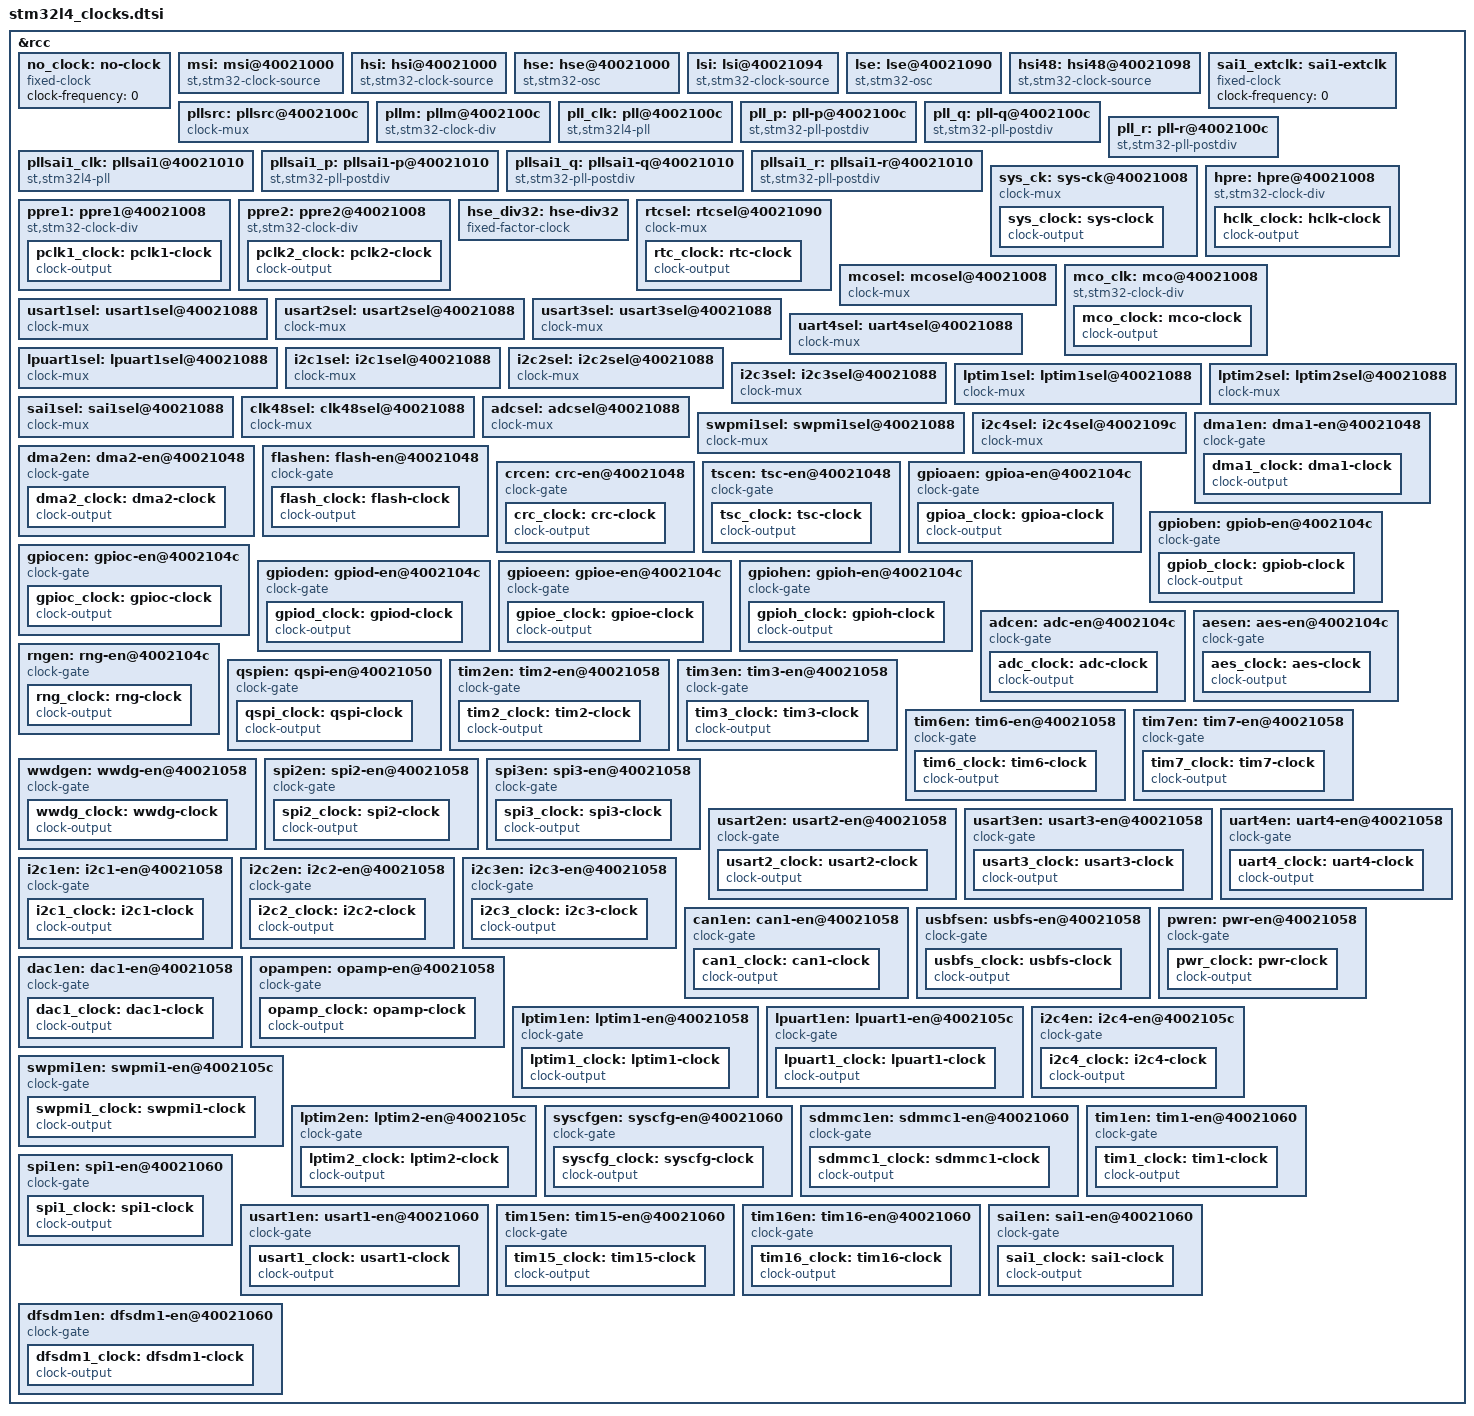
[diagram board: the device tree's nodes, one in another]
/*
 * Copyright (c) 2026 Analog Devices Inc.
 *
 * SPDX-License-Identifier: Apache-2.0
 */

/*
 * Clock tree for the STMicroelectronics STM32L4x (RM0394).
 *
 * Modeled on the STM32H7 clock devicetree: every configurable element of
 * the RCC is described as a node, and the 'reg' property of each node points
 * at the register (RCC base 0x4002_1000) used to configure it. Where a node
 * produces an observable output that a consumer can use, a "clock-output"
 * child node is added.
 *
 * Per-peripheral clock enables (e.g. USART2EN) are modeled as "clock-gate"
 * children of their kernel clock mux, each with its own "clock-output" child.
 *
 * RCC register offsets used below (relative to 0x40021000):
 *   RCC_CR          0x00    RCC_ICSCR       0x04    RCC_CFGR        0x08
 *   RCC_PLLCFGR     0x0C    RCC_PLLSAI1CFGR 0x10
 *   RCC_AHB1ENR     0x48    RCC_AHB2ENR     0x4C    RCC_AHB3ENR     0x50
 *   RCC_APB1ENR1    0x58    RCC_APB1ENR2    0x5C    RCC_APB2ENR     0x60
 *   RCC_CCIPR       0x88    RCC_BDCR        0x90    RCC_CSR         0x94
 *   RCC_CRRCR       0x98    RCC_CCIPR2      0x9C
 */

&rcc {
	#address-cells = <1>;
	#size-cells = <1>;

	/* ----------------------------------------------------------------- */
	/* Root clock sources (oscillators)                                  */
	/* ----------------------------------------------------------------- */

	no_clock: no-clock {
		compatible = "fixed-clock";
		#clock-cells = <0>;
		clock-frequency = <0>;
	};

	msi: msi@40021000 {
		/*
		 * Multi-Speed Internal RC oscillator (100 kHz - 48 MHz).
		 * Default after reset: 4 MHz (MSIRANGE = 6).
		 */
		compatible = "st,stm32-clock-source";
		#clock-cells = <1>;
		/* RCC_CR[MSION] */
		reg = <0x40021000 0x1>;
		offset = <0x0>;
		ready-offset = <0x1>;
		frequency = <4000000>;
	};

	hsi: hsi@40021000 {
		/* 16 MHz high-speed internal RC oscillator */
		compatible = "st,stm32-clock-source";
		#clock-cells = <1>;
		/* RCC_CR[HSION] */
		reg = <0x40021000 0x1>;
		offset = <0x8>;
		ready-offset = <0xa>;
		frequency = <16000000>;
	};

	hse: hse@40021000 {
		/* External high-speed oscillator (crystal or bypass, 4-48 MHz) */
		compatible = "st,stm32-osc";
		#clock-cells = <2>;
		/* RCC_CR[HSEON] */
		reg = <0x40021000 0x1>;
		offset = <0x10>;
		ready-offset = <0x11>;
		bypass-offset = <0x12>;
		frequency = <8000000>;
		#address-cells = <1>;
		#size-cells = <1>;
	};

	lsi: lsi@40021094 {
		/* ~32 kHz low-speed internal RC oscillator */
		compatible = "st,stm32-clock-source";
		#clock-cells = <1>;
		/* RCC_CSR[LSION] */
		reg = <0x40021094 0x1>;
		offset = <0x0>;
		ready-offset = <0x1>;
		frequency = <32000>;
	};

	lse: lse@40021090 {
		/* 32.768 kHz external low-speed oscillator (backup domain) */
		compatible = "st,stm32-osc";
		#clock-cells = <2>;
		/* RCC_BDCR[LSEON] */
		reg = <0x40021090 0x1>;
		offset = <0x0>;
		ready-offset = <0x1>;
		bypass-offset = <0x2>;
		frequency = <32768>;
	};

	hsi48: hsi48@40021098 {
		/* 48 MHz internal RC oscillator (USB/CRS) */
		compatible = "st,stm32-clock-source";
		#clock-cells = <1>;
		/* RCC_CRRCR[HSI48ON] */
		reg = <0x40021098 0x1>;
		offset = <0x0>;
		ready-offset = <0x1>;
		frequency = <48000000>;
	};

	sai1_extclk: sai1-extclk {
		compatible = "fixed-clock";
		#clock-cells = <0>;
		clock-frequency = <0>;
	};

	/* ----------------------------------------------------------------- */
	/* PLL reference clock source mux and input divider                  */
	/* ----------------------------------------------------------------- */

	/*
	 * RCC_PLLCFGR[PLLSRC] - common source for PLL and PLLSAI1.
	 * 00 = None, 01 = MSI, 10 = HSI16, 11 = HSE
	 */
	pllsrc: pllsrc@4002100c {
		compatible = "clock-mux";
		#clock-cells = <1>;
		reg = <0x4002100c 0x2>;
		offset = <0x0>;
		input-sources = <&no_clock &msi &hsi &hse>;
		#address-cells = <1>;
		#size-cells = <1>;
	};

	/*
	 * RCC_PLLCFGR[PLLM] - shared input divider for all PLLs.
	 * Bits [6:4], 3 bits, div 1..8 (field value + 1).
	 */
	pllm: pllm@4002100c {
		compatible = "st,stm32-clock-div";
		#clock-cells = <1>;
		reg = <0x4002100c 0x1>;
		offset = <0x4>;
		width = <0x3>;
		div-type = "linear-aon";
		input = <&pllsrc>;
	};

	/* ----------------------------------------------------------------- */
	/* Main PLL - VCO and P/Q/R post-dividers                           */
	/* ----------------------------------------------------------------- */

	/*
	 * Main PLL VCO.
	 * RCC_PLLCFGR[PLLN] (bits [14:8]): VCO multiplier (8..86).
	 * f(VCO) = f(PLL input) / PLLM * PLLN
	 * RCC_CR[PLLON] bit 24, PLLRDY bit 25.
	 *
	 * This needs a dedicated STM32L4 PLL driver (compatible "st,stm32l4-pll").
	 */
	pll_clk: pll@4002100c {
		compatible = "st,stm32l4-pll";
		reg = <0x4002100c 0x4>, <0x40021000 0x4>;
		#clock-cells = <2>;
		/* RCC_CR[PLLON] */
		enable-bit = <0x18>;
		input = <&pllm>;
		#address-cells = <1>;
		#size-cells = <1>;
	};

	pll_p: pll-p@4002100c {
		/*
		 * RCC_PLLCFGR[PLLP] bit 17: 0=/7, 1=/17
		 * (or PLLPDIV[4:0] bits [31:27] override when nonzero: /2../31)
		 * RCC_PLLCFGR[PLLPEN] bit 16.
		 */
		compatible = "st,stm32-pll-postdiv";
		div-type = "l4p";
		#clock-cells = <1>;
		enable-offset = <0x10>;
		reg = <0x4002100c 0x4>, <0x4002100c 0x4>;
		offset = <0x1b>;
		width = <0x5>;
		input = <&pll_clk>;
	};

	pll_q: pll-q@4002100c {
		/*
		 * RCC_PLLCFGR[PLLQ] bits [22:21]: 00=2, 01=4, 10=6, 11=8
		 * RCC_PLLCFGR[PLLQEN] bit 20.
		 */
		compatible = "st,stm32-pll-postdiv";
		div-type = "l4";
		#clock-cells = <1>;
		enable-offset = <0x14>;
		reg = <0x4002100c 0x4>, <0x4002100c 0x4>;
		offset = <0x15>;
		width = <0x2>;
		input = <&pll_clk>;
	};

	pll_r: pll-r@4002100c {
		/*
		 * RCC_PLLCFGR[PLLR] bits [26:25]: 00=2, 01=4, 10=6, 11=8
		 * RCC_PLLCFGR[PLLREN] bit 24.
		 */
		compatible = "st,stm32-pll-postdiv";
		div-type = "l4";
		#clock-cells = <1>;
		enable-offset = <0x18>;
		reg = <0x4002100c 0x4>, <0x4002100c 0x4>;
		offset = <0x19>;
		width = <0x2>;
		input = <&pll_clk>;
	};

	/* ----------------------------------------------------------------- */
	/* PLLSAI1 - VCO and P/Q/R post-dividers                            */
	/* ----------------------------------------------------------------- */

	/*
	 * PLLSAI1 VCO.
	 * RCC_PLLSAI1CFGR[PLLSAI1N] (bits [14:8]): VCO multiplier (8..86).
	 * Shares PLLSRC and PLLM with main PLL.
	 * RCC_CR[PLLSAI1ON] bit 26, PLLSAI1RDY bit 27.
	 */
	pllsai1_clk: pllsai1@40021010 {
		compatible = "st,stm32l4-pll";
		reg = <0x40021010 0x4>, <0x40021000 0x4>;
		#clock-cells = <2>;
		/* RCC_CR[PLLSAI1ON] */
		enable-bit = <0x1a>;
		input = <&pllm>;
		#address-cells = <1>;
		#size-cells = <1>;
	};

	pllsai1_p: pllsai1-p@40021010 {
		/*
		 * RCC_PLLSAI1CFGR[PLLSAI1P] bit 17: 0=/7, 1=/17
		 * (or PLLSAI1PDIV[4:0] bits [31:27] override when nonzero)
		 * RCC_PLLSAI1CFGR[PLLSAI1PEN] bit 16.
		 */
		compatible = "st,stm32-pll-postdiv";
		div-type = "l4p";
		#clock-cells = <1>;
		enable-offset = <0x10>;
		reg = <0x40021010 0x4>, <0x40021010 0x4>;
		offset = <0x1b>;
		width = <0x5>;
		input = <&pllsai1_clk>;
	};

	pllsai1_q: pllsai1-q@40021010 {
		/*
		 * RCC_PLLSAI1CFGR[PLLSAI1Q] bits [22:21]: 00=2, 01=4, 10=6, 11=8
		 * RCC_PLLSAI1CFGR[PLLSAI1QEN] bit 20.
		 */
		compatible = "st,stm32-pll-postdiv";
		div-type = "l4";
		#clock-cells = <1>;
		enable-offset = <0x14>;
		reg = <0x40021010 0x4>, <0x40021010 0x4>;
		offset = <0x15>;
		width = <0x2>;
		input = <&pllsai1_clk>;
	};

	pllsai1_r: pllsai1-r@40021010 {
		/*
		 * RCC_PLLSAI1CFGR[PLLSAI1R] bits [26:25]: 00=2, 01=4, 10=6, 11=8
		 * RCC_PLLSAI1CFGR[PLLSAI1REN] bit 24.
		 */
		compatible = "st,stm32-pll-postdiv";
		div-type = "l4";
		#clock-cells = <1>;
		enable-offset = <0x18>;
		reg = <0x40021010 0x4>, <0x40021010 0x4>;
		offset = <0x19>;
		width = <0x2>;
		input = <&pllsai1_clk>;
	};

	/* ----------------------------------------------------------------- */
	/* System clock (SYSCLK) and bus clock generation                    */
	/* ----------------------------------------------------------------- */

	sys_ck: sys-ck@40021008 {
		/*
		 * RCC_CFGR[SW] bits [1:0] - system clock source mux.
		 * 00 = MSI, 01 = HSI16, 10 = HSE, 11 = PLL_R
		 */
		compatible = "clock-mux";
		#clock-cells = <1>;
		reg = <0x40021008 0x2>;
		offset = <0x0>;
		input-sources = <&msi &hsi &hse &pll_r>;

		sys_clock: sys-clock {
			compatible = "clock-output";
			#clock-cells = <0>;
		};
	};

	hpre: hpre@40021008 {
		/*
		 * RCC_CFGR[HPRE] bits [7:4] - AHB prescaler.
		 * 0xxx=/1, 1000=/2, 1001=/4, ..., 1111=/512
		 */
		compatible = "st,stm32-clock-div";
		#clock-cells = <1>;
		reg = <0x40021008 0x1>;
		offset = <0x4>;
		width = <0x4>;
		div-type = "pow2";
		input = <&sys_ck>;

		hclk_clock: hclk-clock {
			compatible = "clock-output";
			#clock-cells = <0>;
		};
	};

	ppre1: ppre1@40021008 {
		/*
		 * RCC_CFGR[PPRE1] bits [10:8] - APB1 prescaler.
		 * 0xx=HCLK/1, 100=/2, 101=/4, 110=/8, 111=/16
		 */
		compatible = "st,stm32-clock-div";
		#clock-cells = <1>;
		reg = <0x40021008 0x1>;
		offset = <0x8>;
		width = <0x3>;
		div-type = "pow2";
		input = <&hpre>;

		pclk1_clock: pclk1-clock {
			compatible = "clock-output";
			#clock-cells = <0>;
		};
	};

	ppre2: ppre2@40021008 {
		/*
		 * RCC_CFGR[PPRE2] bits [13:11] - APB2 prescaler.
		 * 0xx=HCLK/1, 100=/2, 101=/4, 110=/8, 111=/16
		 */
		compatible = "st,stm32-clock-div";
		#clock-cells = <1>;
		reg = <0x40021008 0x2>;
		offset = <0xb>;
		width = <0x3>;
		div-type = "pow2";
		input = <&hpre>;

		pclk2_clock: pclk2-clock {
			compatible = "clock-output";
			#clock-cells = <0>;
		};
	};

	/* ----------------------------------------------------------------- */
	/* RTC clock - RCC_BDCR[RTCSEL]                                      */
	/* ----------------------------------------------------------------- */

	hse_div32: hse-div32 {
		compatible = "fixed-factor-clock";
		#clock-cells = <0>;
		clock-div = <32>;
		clock-mult = <1>;
		clocks = <&hse 0 0>;
	};

	rtcsel: rtcsel@40021090 {
		/*
		 * RCC_BDCR[RTCSEL] bits [9:8] - RTC clock source mux.
		 * 00 = None, 01 = LSE, 10 = LSI, 11 = HSE/32
		 */
		compatible = "clock-mux";
		#clock-cells = <1>;
		reg = <0x40021090 0x2>;
		offset = <0x8>;
		input-sources = <&no_clock &lse &lsi &hse_div32>;

		rtc_clock: rtc-clock {
			compatible = "clock-output";
			#clock-cells = <0>;
		};
	};

	/* ----------------------------------------------------------------- */
	/* Micro-controller clock output (MCO) - RCC_CFGR                    */
	/* ----------------------------------------------------------------- */

	mcosel: mcosel@40021008 {
		/*
		 * RCC_CFGR[MCOSEL] bits [27:24] - MCO source mux.
		 * 0000=disabled, 0001=SYSCLK, 0010=MSI, 0011=HSI16,
		 * 0100=HSE, 0101=PLL, 0110=LSI, 0111=LSE, 1000=HSI48
		 */
		compatible = "clock-mux";
		#clock-cells = <1>;
		reg = <0x40021008 0x4>;
		offset = <0x18>;
		input-sources = <&no_clock &sys_ck &msi &hsi &hse
				 &pll_r &lsi &lse &hsi48>;
		#address-cells = <1>;
		#size-cells = <1>;
	};

	mco_clk: mco@40021008 {
		/*
		 * RCC_CFGR[MCOPRE] bits [30:28] - MCO prescaler.
		 * 000=/1, 001=/2, 010=/4, 011=/8, 100=/16
		 */
		compatible = "st,stm32-clock-div";
		#clock-cells = <1>;
		reg = <0x40021008 0x4>;
		div-type = "linear-aon";
		offset = <0x1c>;
		width = <0x3>;
		input = <&mcosel>;

		mco_clock: mco-clock {
			compatible = "clock-output";
			#clock-cells = <0>;
		};
	};

	/* ----------------------------------------------------------------- */
	/* Peripheral kernel clock muxes (RCC_CCIPR @ 0x88)                  */
	/* ----------------------------------------------------------------- */

	usart1sel: usart1sel@40021088 {
		/*
		 * RCC_CCIPR[USART1SEL] bits [1:0].
		 * 00=PCLK2, 01=SYSCLK, 10=HSI16, 11=LSE
		 */
		compatible = "clock-mux";
		#clock-cells = <1>;
		reg = <0x40021088 0x2>;
		offset = <0x0>;
		input-sources = <&ppre2 &sys_ck &hsi &lse>;
	};

	usart2sel: usart2sel@40021088 {
		/*
		 * RCC_CCIPR[USART2SEL] bits [3:2].
		 * 00=PCLK1, 01=SYSCLK, 10=HSI16, 11=LSE
		 */
		compatible = "clock-mux";
		#clock-cells = <1>;
		reg = <0x40021088 0x2>;
		offset = <0x2>;
		input-sources = <&ppre1 &sys_ck &hsi &lse>;
	};

	usart3sel: usart3sel@40021088 {
		/*
		 * RCC_CCIPR[USART3SEL] bits [5:4].
		 * 00=PCLK1, 01=SYSCLK, 10=HSI16, 11=LSE
		 */
		compatible = "clock-mux";
		#clock-cells = <1>;
		reg = <0x40021088 0x2>;
		offset = <0x4>;
		input-sources = <&ppre1 &sys_ck &hsi &lse>;
	};

	uart4sel: uart4sel@40021088 {
		/*
		 * RCC_CCIPR[UART4SEL] bits [7:6].
		 * 00=PCLK1, 01=SYSCLK, 10=HSI16, 11=LSE
		 */
		compatible = "clock-mux";
		#clock-cells = <1>;
		reg = <0x40021088 0x2>;
		offset = <0x6>;
		input-sources = <&ppre1 &sys_ck &hsi &lse>;
	};

	lpuart1sel: lpuart1sel@40021088 {
		/*
		 * RCC_CCIPR[LPUART1SEL] bits [11:10].
		 * 00=PCLK1, 01=SYSCLK, 10=HSI16, 11=LSE
		 */
		compatible = "clock-mux";
		#clock-cells = <1>;
		reg = <0x40021088 0x2>;
		offset = <0xa>;
		input-sources = <&ppre1 &sys_ck &hsi &lse>;
	};

	i2c1sel: i2c1sel@40021088 {
		/*
		 * RCC_CCIPR[I2C1SEL] bits [13:12].
		 * 00=PCLK1, 01=SYSCLK, 10=HSI16, 11=reserved
		 */
		compatible = "clock-mux";
		#clock-cells = <1>;
		reg = <0x40021088 0x2>;
		offset = <0xc>;
		input-sources = <&ppre1 &sys_ck &hsi>;
	};

	i2c2sel: i2c2sel@40021088 {
		/*
		 * RCC_CCIPR[I2C2SEL] bits [15:14].
		 * 00=PCLK1, 01=SYSCLK, 10=HSI16, 11=reserved
		 */
		compatible = "clock-mux";
		#clock-cells = <1>;
		reg = <0x40021088 0x2>;
		offset = <0xe>;
		input-sources = <&ppre1 &sys_ck &hsi>;
	};

	i2c3sel: i2c3sel@40021088 {
		/*
		 * RCC_CCIPR[I2C3SEL] bits [17:16].
		 * 00=PCLK1, 01=SYSCLK, 10=HSI16, 11=reserved
		 */
		compatible = "clock-mux";
		#clock-cells = <1>;
		reg = <0x40021088 0x3>;
		offset = <0x10>;
		input-sources = <&ppre1 &sys_ck &hsi>;
	};

	lptim1sel: lptim1sel@40021088 {
		/*
		 * RCC_CCIPR[LPTIM1SEL] bits [19:18].
		 * 00=PCLK1, 01=LSI, 10=HSI16, 11=LSE
		 */
		compatible = "clock-mux";
		#clock-cells = <1>;
		reg = <0x40021088 0x3>;
		offset = <0x12>;
		input-sources = <&ppre1 &lsi &hsi &lse>;
	};

	lptim2sel: lptim2sel@40021088 {
		/*
		 * RCC_CCIPR[LPTIM2SEL] bits [21:20].
		 * 00=PCLK1, 01=LSI, 10=HSI16, 11=LSE
		 */
		compatible = "clock-mux";
		#clock-cells = <1>;
		reg = <0x40021088 0x3>;
		offset = <0x14>;
		input-sources = <&ppre1 &lsi &hsi &lse>;
	};

	sai1sel: sai1sel@40021088 {
		/*
		 * RCC_CCIPR[SAI1SEL] bits [23:22].
		 * 00=PLLSAI1_P, 01=reserved, 10=PLL_P, 11=SAI1_EXTCLK
		 */
		compatible = "clock-mux";
		#clock-cells = <1>;
		reg = <0x40021088 0x3>;
		offset = <0x16>;
		input-sources = <&pllsai1_p &no_clock &pll_p &sai1_extclk>;
	};

	clk48sel: clk48sel@40021088 {
		/*
		 * RCC_CCIPR[CLK48SEL] bits [27:26].
		 * 00=HSI48, 01=PLLSAI1_Q, 10=PLL_Q, 11=MSI
		 */
		compatible = "clock-mux";
		#clock-cells = <1>;
		reg = <0x40021088 0x4>;
		offset = <0x1a>;
		input-sources = <&hsi48 &pllsai1_q &pll_q &msi>;
	};

	adcsel: adcsel@40021088 {
		/*
		 * RCC_CCIPR[ADCSEL] bits [29:28].
		 * 00=None, 01=PLLSAI1_R, 10=reserved, 11=SYSCLK
		 */
		compatible = "clock-mux";
		#clock-cells = <1>;
		reg = <0x40021088 0x4>;
		offset = <0x1c>;
		input-sources = <&no_clock &pllsai1_r &no_clock &sys_ck>;
	};

	swpmi1sel: swpmi1sel@40021088 {
		/*
		 * RCC_CCIPR[SWPMI1SEL] bit 30.
		 * 0=PCLK1, 1=HSI16
		 */
		compatible = "clock-mux";
		#clock-cells = <1>;
		reg = <0x40021088 0x1>;
		offset = <0x1e>;
		input-sources = <&ppre1 &hsi>;
	};

	/* ----------------------------------------------------------------- */
	/* RCC_CCIPR2 @ 0x9C                                                 */
	/* ----------------------------------------------------------------- */

	i2c4sel: i2c4sel@4002109c {
		/*
		 * RCC_CCIPR2[I2C4SEL] bits [1:0].
		 * 00=PCLK1, 01=SYSCLK, 10=HSI16, 11=reserved
		 */
		compatible = "clock-mux";
		#clock-cells = <1>;
		reg = <0x4002109c 0x2>;
		offset = <0x0>;
		input-sources = <&ppre1 &sys_ck &hsi>;
	};

	/* ----------------------------------------------------------------- */
	/* Clock gates                                                       */
	/* ----------------------------------------------------------------- */

	/* --- AHB1 peripherals (RCC_AHB1ENR @ 0x48) --- */

	dma1en: dma1-en@40021048 {
		/* RCC_AHB1ENR[DMA1EN] bit 0 */
		compatible = "clock-gate";
		#clock-cells = <1>;
		reg = <0x40021048 0x1>;
		offset = <0x0>;
		input = <&hpre>;

		dma1_clock: dma1-clock {
			compatible = "clock-output";
			#clock-cells = <0>;
		};
	};

	dma2en: dma2-en@40021048 {
		/* RCC_AHB1ENR[DMA2EN] bit 1 */
		compatible = "clock-gate";
		#clock-cells = <1>;
		reg = <0x40021048 0x1>;
		offset = <0x1>;
		input = <&hpre>;

		dma2_clock: dma2-clock {
			compatible = "clock-output";
			#clock-cells = <0>;
		};
	};

	flashen: flash-en@40021048 {
		/* RCC_AHB1ENR[FLASHEN] bit 8 */
		compatible = "clock-gate";
		#clock-cells = <1>;
		reg = <0x40021048 0x1>;
		offset = <0x8>;
		input = <&hpre>;

		flash_clock: flash-clock {
			compatible = "clock-output";
			#clock-cells = <0>;
		};
	};

	crcen: crc-en@40021048 {
		/* RCC_AHB1ENR[CRCEN] bit 12 */
		compatible = "clock-gate";
		#clock-cells = <1>;
		reg = <0x40021048 0x1>;
		offset = <0xc>;
		input = <&hpre>;

		crc_clock: crc-clock {
			compatible = "clock-output";
			#clock-cells = <0>;
		};
	};

	tscen: tsc-en@40021048 {
		/* RCC_AHB1ENR[TSCEN] bit 16 */
		compatible = "clock-gate";
		#clock-cells = <1>;
		reg = <0x40021048 0x1>;
		offset = <0x10>;
		input = <&hpre>;

		tsc_clock: tsc-clock {
			compatible = "clock-output";
			#clock-cells = <0>;
		};
	};

	/* --- AHB2 peripherals (RCC_AHB2ENR @ 0x4C) --- */

	gpioaen: gpioa-en@4002104c {
		/* RCC_AHB2ENR[GPIOAEN] bit 0 */
		compatible = "clock-gate";
		#clock-cells = <1>;
		reg = <0x4002104c 0x1>;
		offset = <0x0>;
		input = <&hpre>;

		gpioa_clock: gpioa-clock {
			compatible = "clock-output";
			#clock-cells = <0>;
		};
	};

	gpioben: gpiob-en@4002104c {
		/* RCC_AHB2ENR[GPIOBEN] bit 1 */
		compatible = "clock-gate";
		#clock-cells = <1>;
		reg = <0x4002104c 0x1>;
		offset = <0x1>;
		input = <&hpre>;

		gpiob_clock: gpiob-clock {
			compatible = "clock-output";
			#clock-cells = <0>;
		};
	};

	gpiocen: gpioc-en@4002104c {
		/* RCC_AHB2ENR[GPIOCEN] bit 2 */
		compatible = "clock-gate";
		#clock-cells = <1>;
		reg = <0x4002104c 0x1>;
		offset = <0x2>;
		input = <&hpre>;

		gpioc_clock: gpioc-clock {
			compatible = "clock-output";
			#clock-cells = <0>;
		};
	};

	gpioden: gpiod-en@4002104c {
		/* RCC_AHB2ENR[GPIODEN] bit 3 */
		compatible = "clock-gate";
		#clock-cells = <1>;
		reg = <0x4002104c 0x1>;
		offset = <0x3>;
		input = <&hpre>;

		gpiod_clock: gpiod-clock {
			compatible = "clock-output";
			#clock-cells = <0>;
		};
	};

	gpioeen: gpioe-en@4002104c {
		/* RCC_AHB2ENR[GPIOEEN] bit 4 */
		compatible = "clock-gate";
		#clock-cells = <1>;
		reg = <0x4002104c 0x1>;
		offset = <0x4>;
		input = <&hpre>;

		gpioe_clock: gpioe-clock {
			compatible = "clock-output";
			#clock-cells = <0>;
		};
	};

	gpiohen: gpioh-en@4002104c {
		/* RCC_AHB2ENR[GPIOHEN] bit 7 */
		compatible = "clock-gate";
		#clock-cells = <1>;
		reg = <0x4002104c 0x1>;
		offset = <0x7>;
		input = <&hpre>;

		gpioh_clock: gpioh-clock {
			compatible = "clock-output";
			#clock-cells = <0>;
		};
	};

	adcen: adc-en@4002104c {
		/* RCC_AHB2ENR[ADCEN] bit 13 */
		compatible = "clock-gate";
		#clock-cells = <1>;
		reg = <0x4002104c 0x1>;
		offset = <0xd>;
		input = <&adcsel>;

		adc_clock: adc-clock {
			compatible = "clock-output";
			#clock-cells = <0>;
		};
	};

	aesen: aes-en@4002104c {
		/* RCC_AHB2ENR[AESEN] bit 16 */
		compatible = "clock-gate";
		#clock-cells = <1>;
		reg = <0x4002104c 0x1>;
		offset = <0x10>;
		input = <&hpre>;

		aes_clock: aes-clock {
			compatible = "clock-output";
			#clock-cells = <0>;
		};
	};

	rngen: rng-en@4002104c {
		/* RCC_AHB2ENR[RNGEN] bit 18 */
		compatible = "clock-gate";
		#clock-cells = <1>;
		reg = <0x4002104c 0x1>;
		offset = <0x12>;
		input = <&clk48sel>;

		rng_clock: rng-clock {
			compatible = "clock-output";
			#clock-cells = <0>;
		};
	};

	/* --- AHB3 peripherals (RCC_AHB3ENR @ 0x50) --- */

	qspien: qspi-en@40021050 {
		/* RCC_AHB3ENR[QSPIEN] bit 8 */
		compatible = "clock-gate";
		#clock-cells = <1>;
		reg = <0x40021050 0x1>;
		offset = <0x8>;
		input = <&hpre>;

		qspi_clock: qspi-clock {
			compatible = "clock-output";
			#clock-cells = <0>;
		};
	};

	/* --- APB1 peripherals (RCC_APB1ENR1 @ 0x58) --- */

	tim2en: tim2-en@40021058 {
		/* RCC_APB1ENR1[TIM2EN] bit 0 */
		compatible = "clock-gate";
		#clock-cells = <1>;
		reg = <0x40021058 0x1>;
		offset = <0x0>;
		input = <&ppre1>;

		tim2_clock: tim2-clock {
			compatible = "clock-output";
			#clock-cells = <0>;
		};
	};

	tim3en: tim3-en@40021058 {
		/* RCC_APB1ENR1[TIM3EN] bit 1 */
		compatible = "clock-gate";
		#clock-cells = <1>;
		reg = <0x40021058 0x1>;
		offset = <0x1>;
		input = <&ppre1>;

		tim3_clock: tim3-clock {
			compatible = "clock-output";
			#clock-cells = <0>;
		};
	};

	tim6en: tim6-en@40021058 {
		/* RCC_APB1ENR1[TIM6EN] bit 4 */
		compatible = "clock-gate";
		#clock-cells = <1>;
		reg = <0x40021058 0x1>;
		offset = <0x4>;
		input = <&ppre1>;

		tim6_clock: tim6-clock {
			compatible = "clock-output";
			#clock-cells = <0>;
		};
	};

	tim7en: tim7-en@40021058 {
		/* RCC_APB1ENR1[TIM7EN] bit 5 */
		compatible = "clock-gate";
		#clock-cells = <1>;
		reg = <0x40021058 0x1>;
		offset = <0x5>;
		input = <&ppre1>;

		tim7_clock: tim7-clock {
			compatible = "clock-output";
			#clock-cells = <0>;
		};
	};

	wwdgen: wwdg-en@40021058 {
		/* RCC_APB1ENR1[WWDGEN] bit 11 */
		compatible = "clock-gate";
		#clock-cells = <1>;
		reg = <0x40021058 0x1>;
		offset = <0xb>;
		input = <&ppre1>;

		wwdg_clock: wwdg-clock {
			compatible = "clock-output";
			#clock-cells = <0>;
		};
	};

	spi2en: spi2-en@40021058 {
		/* RCC_APB1ENR1[SPI2EN] bit 14 */
		compatible = "clock-gate";
		#clock-cells = <1>;
		reg = <0x40021058 0x1>;
		offset = <0xe>;
		input = <&ppre1>;

		spi2_clock: spi2-clock {
			compatible = "clock-output";
			#clock-cells = <0>;
		};
	};

	spi3en: spi3-en@40021058 {
		/* RCC_APB1ENR1[SPI3EN] bit 15 */
		compatible = "clock-gate";
		#clock-cells = <1>;
		reg = <0x40021058 0x1>;
		offset = <0xf>;
		input = <&ppre1>;

		spi3_clock: spi3-clock {
			compatible = "clock-output";
			#clock-cells = <0>;
		};
	};

	usart2en: usart2-en@40021058 {
		/* RCC_APB1ENR1[USART2EN] bit 17 */
		compatible = "clock-gate";
		#clock-cells = <1>;
		reg = <0x40021058 0x1>;
		offset = <0x11>;
		input = <&usart2sel>;

		usart2_clock: usart2-clock {
			compatible = "clock-output";
			#clock-cells = <0>;
		};
	};

	usart3en: usart3-en@40021058 {
		/* RCC_APB1ENR1[USART3EN] bit 18 */
		compatible = "clock-gate";
		#clock-cells = <1>;
		reg = <0x40021058 0x1>;
		offset = <0x12>;
		input = <&usart3sel>;

		usart3_clock: usart3-clock {
			compatible = "clock-output";
			#clock-cells = <0>;
		};
	};

	uart4en: uart4-en@40021058 {
		/* RCC_APB1ENR1[UART4EN] bit 19 */
		compatible = "clock-gate";
		#clock-cells = <1>;
		reg = <0x40021058 0x1>;
		offset = <0x13>;
		input = <&uart4sel>;

		uart4_clock: uart4-clock {
			compatible = "clock-output";
			#clock-cells = <0>;
		};
	};

	i2c1en: i2c1-en@40021058 {
		/* RCC_APB1ENR1[I2C1EN] bit 21 */
		compatible = "clock-gate";
		#clock-cells = <1>;
		reg = <0x40021058 0x1>;
		offset = <0x15>;
		input = <&i2c1sel>;

		i2c1_clock: i2c1-clock {
			compatible = "clock-output";
			#clock-cells = <0>;
		};
	};

	i2c2en: i2c2-en@40021058 {
		/* RCC_APB1ENR1[I2C2EN] bit 22 */
		compatible = "clock-gate";
		#clock-cells = <1>;
		reg = <0x40021058 0x1>;
		offset = <0x16>;
		input = <&i2c2sel>;

		i2c2_clock: i2c2-clock {
			compatible = "clock-output";
			#clock-cells = <0>;
		};
	};

	i2c3en: i2c3-en@40021058 {
		/* RCC_APB1ENR1[I2C3EN] bit 23 */
		compatible = "clock-gate";
		#clock-cells = <1>;
		reg = <0x40021058 0x1>;
		offset = <0x17>;
		input = <&i2c3sel>;

		i2c3_clock: i2c3-clock {
			compatible = "clock-output";
			#clock-cells = <0>;
		};
	};

	can1en: can1-en@40021058 {
		/* RCC_APB1ENR1[CAN1EN] bit 25 */
		compatible = "clock-gate";
		#clock-cells = <1>;
		reg = <0x40021058 0x1>;
		offset = <0x19>;
		input = <&ppre1>;

		can1_clock: can1-clock {
			compatible = "clock-output";
			#clock-cells = <0>;
		};
	};

	usbfsen: usbfs-en@40021058 {
		/* RCC_APB1ENR1[USBFSEN] bit 26 */
		compatible = "clock-gate";
		#clock-cells = <1>;
		reg = <0x40021058 0x1>;
		offset = <0x1a>;
		input = <&clk48sel>;

		usbfs_clock: usbfs-clock {
			compatible = "clock-output";
			#clock-cells = <0>;
		};
	};

	pwren: pwr-en@40021058 {
		/* RCC_APB1ENR1[PWREN] bit 28 */
		compatible = "clock-gate";
		#clock-cells = <1>;
		reg = <0x40021058 0x1>;
		offset = <0x1c>;
		input = <&ppre1>;

		pwr_clock: pwr-clock {
			compatible = "clock-output";
			#clock-cells = <0>;
		};
	};

	dac1en: dac1-en@40021058 {
		/* RCC_APB1ENR1[DAC1EN] bit 29 */
		compatible = "clock-gate";
		#clock-cells = <1>;
		reg = <0x40021058 0x1>;
		offset = <0x1d>;
		input = <&ppre1>;

		dac1_clock: dac1-clock {
			compatible = "clock-output";
			#clock-cells = <0>;
		};
	};

	opampen: opamp-en@40021058 {
		/* RCC_APB1ENR1[OPAMPEN] bit 30 */
		compatible = "clock-gate";
		#clock-cells = <1>;
		reg = <0x40021058 0x1>;
		offset = <0x1e>;
		input = <&ppre1>;

		opamp_clock: opamp-clock {
			compatible = "clock-output";
			#clock-cells = <0>;
		};
	};

	lptim1en: lptim1-en@40021058 {
		/* RCC_APB1ENR1[LPTIM1EN] bit 31 */
		compatible = "clock-gate";
		#clock-cells = <1>;
		reg = <0x40021058 0x1>;
		offset = <0x1f>;
		input = <&lptim1sel>;

		lptim1_clock: lptim1-clock {
			compatible = "clock-output";
			#clock-cells = <0>;
		};
	};

	/* --- APB1 peripherals (RCC_APB1ENR2 @ 0x5C) --- */

	lpuart1en: lpuart1-en@4002105c {
		/* RCC_APB1ENR2[LPUART1EN] bit 0 */
		compatible = "clock-gate";
		#clock-cells = <1>;
		reg = <0x4002105c 0x1>;
		offset = <0x0>;
		input = <&lpuart1sel>;

		lpuart1_clock: lpuart1-clock {
			compatible = "clock-output";
			#clock-cells = <0>;
		};
	};

	i2c4en: i2c4-en@4002105c {
		/* RCC_APB1ENR2[I2C4EN] bit 1 */
		compatible = "clock-gate";
		#clock-cells = <1>;
		reg = <0x4002105c 0x1>;
		offset = <0x1>;
		input = <&i2c4sel>;

		i2c4_clock: i2c4-clock {
			compatible = "clock-output";
			#clock-cells = <0>;
		};
	};

	swpmi1en: swpmi1-en@4002105c {
		/* RCC_APB1ENR2[SWPMI1EN] bit 2 */
		compatible = "clock-gate";
		#clock-cells = <1>;
		reg = <0x4002105c 0x1>;
		offset = <0x2>;
		input = <&swpmi1sel>;

		swpmi1_clock: swpmi1-clock {
			compatible = "clock-output";
			#clock-cells = <0>;
		};
	};

	lptim2en: lptim2-en@4002105c {
		/* RCC_APB1ENR2[LPTIM2EN] bit 5 */
		compatible = "clock-gate";
		#clock-cells = <1>;
		reg = <0x4002105c 0x1>;
		offset = <0x5>;
		input = <&lptim2sel>;

		lptim2_clock: lptim2-clock {
			compatible = "clock-output";
			#clock-cells = <0>;
		};
	};

	/* --- APB2 peripherals (RCC_APB2ENR @ 0x60) --- */

	syscfgen: syscfg-en@40021060 {
		/* RCC_APB2ENR[SYSCFGEN] bit 0 */
		compatible = "clock-gate";
		#clock-cells = <1>;
		reg = <0x40021060 0x1>;
		offset = <0x0>;
		input = <&ppre2>;

		syscfg_clock: syscfg-clock {
			compatible = "clock-output";
			#clock-cells = <0>;
		};
	};

	sdmmc1en: sdmmc1-en@40021060 {
		/* RCC_APB2ENR[SDMMC1EN] bit 10 */
		compatible = "clock-gate";
		#clock-cells = <1>;
		reg = <0x40021060 0x1>;
		offset = <0xa>;
		input = <&clk48sel>;

		sdmmc1_clock: sdmmc1-clock {
			compatible = "clock-output";
			#clock-cells = <0>;
		};
	};

	tim1en: tim1-en@40021060 {
		/* RCC_APB2ENR[TIM1EN] bit 11 */
		compatible = "clock-gate";
		#clock-cells = <1>;
		reg = <0x40021060 0x1>;
		offset = <0xb>;
		input = <&ppre2>;

		tim1_clock: tim1-clock {
			compatible = "clock-output";
			#clock-cells = <0>;
		};
	};

	spi1en: spi1-en@40021060 {
		/* RCC_APB2ENR[SPI1EN] bit 12 */
		compatible = "clock-gate";
		#clock-cells = <1>;
		reg = <0x40021060 0x1>;
		offset = <0xc>;
		input = <&ppre2>;

		spi1_clock: spi1-clock {
			compatible = "clock-output";
			#clock-cells = <0>;
		};
	};

	usart1en: usart1-en@40021060 {
		/* RCC_APB2ENR[USART1EN] bit 14 */
		compatible = "clock-gate";
		#clock-cells = <1>;
		reg = <0x40021060 0x1>;
		offset = <0xe>;
		input = <&usart1sel>;

		usart1_clock: usart1-clock {
			compatible = "clock-output";
			#clock-cells = <0>;
		};
	};

	tim15en: tim15-en@40021060 {
		/* RCC_APB2ENR[TIM15EN] bit 16 */
		compatible = "clock-gate";
		#clock-cells = <1>;
		reg = <0x40021060 0x1>;
		offset = <0x10>;
		input = <&ppre2>;

		tim15_clock: tim15-clock {
			compatible = "clock-output";
			#clock-cells = <0>;
		};
	};

	tim16en: tim16-en@40021060 {
		/* RCC_APB2ENR[TIM16EN] bit 17 */
		compatible = "clock-gate";
		#clock-cells = <1>;
		reg = <0x40021060 0x1>;
		offset = <0x11>;
		input = <&ppre2>;

		tim16_clock: tim16-clock {
			compatible = "clock-output";
			#clock-cells = <0>;
		};
	};

	sai1en: sai1-en@40021060 {
		/* RCC_APB2ENR[SAI1EN] bit 21 */
		compatible = "clock-gate";
		#clock-cells = <1>;
		reg = <0x40021060 0x1>;
		offset = <0x15>;
		input = <&sai1sel>;

		sai1_clock: sai1-clock {
			compatible = "clock-output";
			#clock-cells = <0>;
		};
	};

	dfsdm1en: dfsdm1-en@40021060 {
		/* RCC_APB2ENR[DFSDM1EN] bit 24 */
		compatible = "clock-gate";
		#clock-cells = <1>;
		reg = <0x40021060 0x1>;
		offset = <0x18>;
		input = <&ppre2>;

		dfsdm1_clock: dfsdm1-clock {
			compatible = "clock-output";
			#clock-cells = <0>;
		};
	};
};
